# WKUP_CTRL_MMR0_CFG0 register map
Vendor: Texas Instruments
Registers are 32-bit, read-write, reset 0x0 unless marked. A register's access mark holds for its fields unless they carry their own. Offsets are as the file gives them; [hi:lo] are bit positions.

## WKUP_CTRL_MMR0_CFG0 (part 6 of 11)
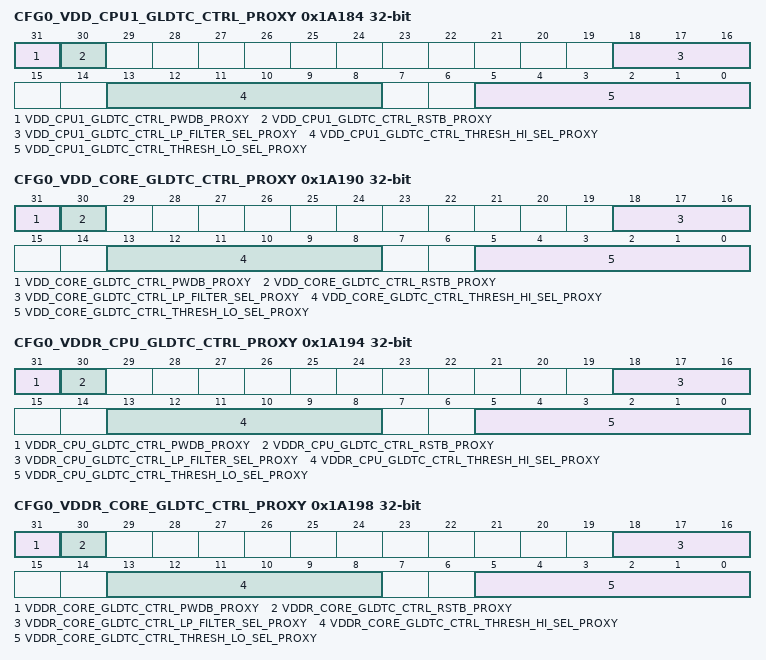
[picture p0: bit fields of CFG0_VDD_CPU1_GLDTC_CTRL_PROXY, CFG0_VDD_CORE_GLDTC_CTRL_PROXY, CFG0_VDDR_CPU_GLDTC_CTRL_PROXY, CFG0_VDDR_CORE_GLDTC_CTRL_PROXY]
0x1A184 CFG0_VDD_CPU1_GLDTC_CTRL_PROXY
  [31] VDD_CPU1_GLDTC_CTRL_PWDB_PROXY — Power down - active low. 0 - Disable all functions 1 - Enable glitch detectors
  [30] VDD_CPU1_GLDTC_CTRL_RSTB_PROXY — Reset - active low. To ensure proper operation, rstb must be not be de-asserted for at least 100 ns after power-up (pwdb de-asserted). Additionally, rstb must be toggled low at least 200 ns after any change in threshold or low-pass filter settings to prevent abnormal trigger events. 0 - Reset glitch detector flags 1 - Glitch detection flags are enabled
  [18:16] VDD_CPU1_GLDTC_CTRL_LP_FILTER_SEL_PROXY — Selects the glitch detect low-pass filter bandwidth Field values (Others are reserved): 3'b000 - 150 kHz 3'b001 - 125 kHz 3'b010 - 100 kHz 3'b011 - 80 kHz 3'b100 - 60 kHz 3'b101 - 45 kHz 3'b110 - 30 kHz 3'b111 - 15 kHz
  [13:8] VDD_CPU1_GLDTC_CTRL_THRESH_HI_SEL_PROXY — Selects the high voltage glitch threshold as a percentage of the monitored voltage Field values (Others are reserved): 6'b000000 - 93.5% of VDD 6'b000001 - 94.0% of VDD 6'b000010 - 94.5% of VDD 6'b000011 - 95.0% of VDD 6'b000100 - 95.5% of VDD 6'b000101 - 96.0% of VDD 6'b000110 - 96.5% of VDD 6'b000111 - 97.0% of VDD 6'b001000 - 97.5% of VDD 6'b001001 - 98.0% of VDD 6'b001010 - 98.5% of VDD 6'b001011 - 99.0% of VDD 6'b001100 - 99.5% of VDD 6'b001101 - 100.0% of VDD 6'b001110 - 100.5% of VDD 6'b001111 - 101.0% of VDD 6'b010000 - 101.5% of VDD 6'b010001 - 102.0% of VDD 6'b010010 - 102.5% of VDD 6'b010011 - 103.0% of VDD 6'b010100 - 103.5% of VDD 6'b010101 - 104.0% of VDD 6'b010110 - 104.5% of VDD 6'b010111 - 105.0% of VDD 6'b011000 - 105.5% of VDD 6'b011001 - 106.0% of VDD 6'b011010 - 106.5% of VDD 6'b011011 - 107.0% of VDD 6'b011100 - 107.5% of VDD 6'b011101 - 108.0% of VDD 6'b011110 - 108.5% of VDD 6'b011111 - 109.0% of VDD 6'b100000 - 109.5% of VDD 6'b100001 - 110.0% of VDD 6'b100010 - 111.0% of VDD 6'b100011 - 112.0% of VDD 6'b100100 - 113.0% of VDD 6'b100101 - 114.0% of VDD 6'b100110 - 115.0% of VDD 6'b100111 - 116.0% of VDD 6'b101000 - 117.0% of VDD 6'b101001 - 118.0% of VDD 6'b101010 - 119.0% of VDD 6'b101011 - 120.0% of VDD 6'b101100 - 121.0% of VDD 6'b101101 - 122.0% of VDD 6'b101110 - 123.0% of VDD 6'b101111 - 124.0% of VDD 6'b110000 - 125.0% of VDD 6'b110001 - 126.0% of VDD 6'b110010 - 127.0% of VDD 6'b110011 - 128.0% of VDD 6'b110100 - 129.0% of VDD 6'b110101 - 130.0% of VDD 6'b110110 - 131.0% of VDD 6'b110111 - 132.0% of VDD 6'b111000 - 133.0% of VDD 6'b111001 - 134.0% of VDD 6'b111010 - 135.0% of VDD 6'b111011 - 136.0% of VDD 6'b111100 - 137.0% of VDD 6'b111101 - 138.0% of VDD 6'b111110 - 139.0% of VDD 6'b111111 - 140.0% of VDD
  [5:0] VDD_CPU1_GLDTC_CTRL_THRESH_LO_SEL_PROXY — Selects the low voltage glitch threshold as a percentage of the monitored voltage Field values (Others are reserved): 6'b000000 - 106.5% of VDD 6'b000001 - 106.0% of VDD 6'b000010 - 105.5% of VDD 6'b000011 - 105.0% of VDD 6'b000100 - 104.5% of VDD 6'b000101 - 104.0% of VDD 6'b000110 - 103.5% of VDD 6'b000111 - 103.0% of VDD 6'b001000 - 102.5% of VDD 6'b001001 - 102.0% of VDD 6'b001010 - 101.5% of VDD 6'b001011 - 101.0% of VDD 6'b001100 - 100.5% of VDD 6'b001101 - 100.0% of VDD 6'b001110 - 99.5% of VDD 6'b001111 - 99.0% of VDD 6'b010000 - 98.5% of VDD 6'b010001 - 98.0% of VDD 6'b010010 - 97.5% of VDD 6'b010011 - 97.0% of VDD 6'b010100 - 96.5% of VDD 6'b010101 - 96.0% of VDD 6'b010110 - 95.5% of VDD 6'b010111 - 95.0% of VDD 6'b011000 - 94.5% of VDD 6'b011001 - 94.0% of VDD 6'b011010 - 93.5% of VDD 6'b011011 - 93.0% of VDD 6'b011100 - 92.5% of VDD 6'b011101 - 92.0% of VDD 6'b011110 - 91.5% of VDD 6'b011111 - 91.0% of VDD 6'b100000 - 90.5% of VDD 6'b100001 - 90.0% of VDD 6'b100010 - 89.0% of VDD 6'b100011 - 88.0% of VDD 6'b100100 - 87.0% of VDD 6'b100101 - 86.0% of VDD 6'b100110 - 85.0% of VDD 6'b100111 - 84.0% of VDD 6'b101000 - 83.0% of VDD 6'b101001 - 82.0% of VDD 6'b101010 - 81.0% of VDD 6'b101011 - 80.0% of VDD 6'b101100 - 79.0% of VDD 6'b101101 - 78.0% of VDD 6'b101110 - 77.0% of VDD 6'b101111 - 76.0% of VDD 6'b110000 - 75.0% of VDD 6'b110001 - 74.0% of VDD 6'b110010 - 73.0% of VDD 6'b110011 - 72.0% of VDD 6'b110100 - 71.0% of VDD 6'b110101 - 70.0% of VDD 6'b110110 - 69.0% of VDD 6'b110111 - 68.0% of VDD 6'b111000 - 67.0% of VDD 6'b111001 - 66.0% of VDD 6'b111010 - 65.0% of VDD 6'b111011 - 64.0% of VDD 6'b111100 - 63.0% of VDD 6'b111101 - 62.0% of VDD 6'b111110 - 61.0% of VDD 6'b111111 - 60.0% of VDD
0x1A190 CFG0_VDD_CORE_GLDTC_CTRL_PROXY — Controls the voltage glitch detector circuit monitoring the VDD_CORE voltage domain
  [31] VDD_CORE_GLDTC_CTRL_PWDB_PROXY — Power down - active low. 0 - Disable all functions 1 - Enable glitch detectors
  [30] VDD_CORE_GLDTC_CTRL_RSTB_PROXY — Reset - active low. To ensure proper operation, rstb must be not be de-asserted for at least 100 ns after power-up (pwdb de-asserted). Additionally, rstb must be toggled low at least 200 ns after any change in threshold or low-pass filter settings to prevent abnormal trigger events. 0 - Reset glitch detector flags 1 - Glitch detection flags are enabled
  [18:16] VDD_CORE_GLDTC_CTRL_LP_FILTER_SEL_PROXY — Selects the glitch detect low-pass filter bandwidth Field values (Others are reserved): 3'b000 - 150 kHz 3'b001 - 125 kHz 3'b010 - 100 kHz 3'b011 - 80 kHz 3'b100 - 60 kHz 3'b101 - 45 kHz 3'b110 - 30 kHz 3'b111 - 15 kHz
  [13:8] VDD_CORE_GLDTC_CTRL_THRESH_HI_SEL_PROXY — Selects the high voltage glitch threshold as a percentage of the monitored voltage Field values (Others are reserved): 6'b000000 - 93.5% of VDD 6'b000001 - 94.0% of VDD 6'b000010 - 94.5% of VDD 6'b000011 - 95.0% of VDD 6'b000100 - 95.5% of VDD 6'b000101 - 96.0% of VDD 6'b000110 - 96.5% of VDD 6'b000111 - 97.0% of VDD 6'b001000 - 97.5% of VDD 6'b001001 - 98.0% of VDD 6'b001010 - 98.5% of VDD 6'b001011 - 99.0% of VDD 6'b001100 - 99.5% of VDD 6'b001101 - 100.0% of VDD 6'b001110 - 100.5% of VDD 6'b001111 - 101.0% of VDD 6'b010000 - 101.5% of VDD 6'b010001 - 102.0% of VDD 6'b010010 - 102.5% of VDD 6'b010011 - 103.0% of VDD 6'b010100 - 103.5% of VDD 6'b010101 - 104.0% of VDD 6'b010110 - 104.5% of VDD 6'b010111 - 105.0% of VDD 6'b011000 - 105.5% of VDD 6'b011001 - 106.0% of VDD 6'b011010 - 106.5% of VDD 6'b011011 - 107.0% of VDD 6'b011100 - 107.5% of VDD 6'b011101 - 108.0% of VDD 6'b011110 - 108.5% of VDD 6'b011111 - 109.0% of VDD 6'b100000 - 109.5% of VDD 6'b100001 - 110.0% of VDD 6'b100010 - 111.0% of VDD 6'b100011 - 112.0% of VDD 6'b100100 - 113.0% of VDD 6'b100101 - 114.0% of VDD 6'b100110 - 115.0% of VDD 6'b100111 - 116.0% of VDD 6'b101000 - 117.0% of VDD 6'b101001 - 118.0% of VDD 6'b101010 - 119.0% of VDD 6'b101011 - 120.0% of VDD 6'b101100 - 121.0% of VDD 6'b101101 - 122.0% of VDD 6'b101110 - 123.0% of VDD 6'b101111 - 124.0% of VDD 6'b110000 - 125.0% of VDD 6'b110001 - 126.0% of VDD 6'b110010 - 127.0% of VDD 6'b110011 - 128.0% of VDD 6'b110100 - 129.0% of VDD 6'b110101 - 130.0% of VDD 6'b110110 - 131.0% of VDD 6'b110111 - 132.0% of VDD 6'b111000 - 133.0% of VDD 6'b111001 - 134.0% of VDD 6'b111010 - 135.0% of VDD 6'b111011 - 136.0% of VDD 6'b111100 - 137.0% of VDD 6'b111101 - 138.0% of VDD 6'b111110 - 139.0% of VDD 6'b111111 - 140.0% of VDD
  [5:0] VDD_CORE_GLDTC_CTRL_THRESH_LO_SEL_PROXY — Selects the low voltage glitch threshold as a percentage of the monitored voltage Field values (Others are reserved): 6'b000000 - 106.5% of VDD 6'b000001 - 106.0% of VDD 6'b000010 - 105.5% of VDD 6'b000011 - 105.0% of VDD 6'b000100 - 104.5% of VDD 6'b000101 - 104.0% of VDD 6'b000110 - 103.5% of VDD 6'b000111 - 103.0% of VDD 6'b001000 - 102.5% of VDD 6'b001001 - 102.0% of VDD 6'b001010 - 101.5% of VDD 6'b001011 - 101.0% of VDD 6'b001100 - 100.5% of VDD 6'b001101 - 100.0% of VDD 6'b001110 - 99.5% of VDD 6'b001111 - 99.0% of VDD 6'b010000 - 98.5% of VDD 6'b010001 - 98.0% of VDD 6'b010010 - 97.5% of VDD 6'b010011 - 97.0% of VDD 6'b010100 - 96.5% of VDD 6'b010101 - 96.0% of VDD 6'b010110 - 95.5% of VDD 6'b010111 - 95.0% of VDD 6'b011000 - 94.5% of VDD 6'b011001 - 94.0% of VDD 6'b011010 - 93.5% of VDD 6'b011011 - 93.0% of VDD 6'b011100 - 92.5% of VDD 6'b011101 - 92.0% of VDD 6'b011110 - 91.5% of VDD 6'b011111 - 91.0% of VDD 6'b100000 - 90.5% of VDD 6'b100001 - 90.0% of VDD 6'b100010 - 89.0% of VDD 6'b100011 - 88.0% of VDD 6'b100100 - 87.0% of VDD 6'b100101 - 86.0% of VDD 6'b100110 - 85.0% of VDD 6'b100111 - 84.0% of VDD 6'b101000 - 83.0% of VDD 6'b101001 - 82.0% of VDD 6'b101010 - 81.0% of VDD 6'b101011 - 80.0% of VDD 6'b101100 - 79.0% of VDD 6'b101101 - 78.0% of VDD 6'b101110 - 77.0% of VDD 6'b101111 - 76.0% of VDD 6'b110000 - 75.0% of VDD 6'b110001 - 74.0% of VDD 6'b110010 - 73.0% of VDD 6'b110011 - 72.0% of VDD 6'b110100 - 71.0% of VDD 6'b110101 - 70.0% of VDD 6'b110110 - 69.0% of VDD 6'b110111 - 68.0% of VDD 6'b111000 - 67.0% of VDD 6'b111001 - 66.0% of VDD 6'b111010 - 65.0% of VDD 6'b111011 - 64.0% of VDD 6'b111100 - 63.0% of VDD 6'b111101 - 62.0% of VDD 6'b111110 - 61.0% of VDD 6'b111111 - 60.0% of VDD
0x1A194 CFG0_VDDR_CPU_GLDTC_CTRL_PROXY — Controls the voltage glitch detector circuit monitoring the VDDR_CPU 0 voltage domain
  [31] VDDR_CPU_GLDTC_CTRL_PWDB_PROXY — Power down - active low. 0 - Disable all functions 1 - Enable glitch detectors
  [30] VDDR_CPU_GLDTC_CTRL_RSTB_PROXY — Reset - active low. To ensure proper operation, rstb must be not be de-asserted for at least 100 ns after power-up (pwdb de-asserted). Additionally, rstb must be toggled low at least 200 ns after any change in threshold or low-pass filter settings to prevent abnormal trigger events. 0 - Reset glitch detector flags 1 - Glitch detection flags are enabled
  [18:16] VDDR_CPU_GLDTC_CTRL_LP_FILTER_SEL_PROXY — Selects the glitch detect low-pass filter bandwidth Field values (Others are reserved): 3'b000 - 150 kHz 3'b001 - 125 kHz 3'b010 - 100 kHz 3'b011 - 80 kHz 3'b100 - 60 kHz 3'b101 - 45 kHz 3'b110 - 30 kHz 3'b111 - 15 kHz
  [13:8] VDDR_CPU_GLDTC_CTRL_THRESH_HI_SEL_PROXY — Selects the high voltage glitch threshold as a percentage of the monitored voltage Field values (Others are reserved): 6'b000000 - 93.5% of VDD 6'b000001 - 94.0% of VDD 6'b000010 - 94.5% of VDD 6'b000011 - 95.0% of VDD 6'b000100 - 95.5% of VDD 6'b000101 - 96.0% of VDD 6'b000110 - 96.5% of VDD 6'b000111 - 97.0% of VDD 6'b001000 - 97.5% of VDD 6'b001001 - 98.0% of VDD 6'b001010 - 98.5% of VDD 6'b001011 - 99.0% of VDD 6'b001100 - 99.5% of VDD 6'b001101 - 100.0% of VDD 6'b001110 - 100.5% of VDD 6'b001111 - 101.0% of VDD 6'b010000 - 101.5% of VDD 6'b010001 - 102.0% of VDD 6'b010010 - 102.5% of VDD 6'b010011 - 103.0% of VDD 6'b010100 - 103.5% of VDD 6'b010101 - 104.0% of VDD 6'b010110 - 104.5% of VDD 6'b010111 - 105.0% of VDD 6'b011000 - 105.5% of VDD 6'b011001 - 106.0% of VDD 6'b011010 - 106.5% of VDD 6'b011011 - 107.0% of VDD 6'b011100 - 107.5% of VDD 6'b011101 - 108.0% of VDD 6'b011110 - 108.5% of VDD 6'b011111 - 109.0% of VDD 6'b100000 - 109.5% of VDD 6'b100001 - 110.0% of VDD 6'b100010 - 111.0% of VDD 6'b100011 - 112.0% of VDD 6'b100100 - 113.0% of VDD 6'b100101 - 114.0% of VDD 6'b100110 - 115.0% of VDD 6'b100111 - 116.0% of VDD 6'b101000 - 117.0% of VDD 6'b101001 - 118.0% of VDD 6'b101010 - 119.0% of VDD 6'b101011 - 120.0% of VDD 6'b101100 - 121.0% of VDD 6'b101101 - 122.0% of VDD 6'b101110 - 123.0% of VDD 6'b101111 - 124.0% of VDD 6'b110000 - 125.0% of VDD 6'b110001 - 126.0% of VDD 6'b110010 - 127.0% of VDD 6'b110011 - 128.0% of VDD 6'b110100 - 129.0% of VDD 6'b110101 - 130.0% of VDD 6'b110110 - 131.0% of VDD 6'b110111 - 132.0% of VDD 6'b111000 - 133.0% of VDD 6'b111001 - 134.0% of VDD 6'b111010 - 135.0% of VDD 6'b111011 - 136.0% of VDD 6'b111100 - 137.0% of VDD 6'b111101 - 138.0% of VDD 6'b111110 - 139.0% of VDD 6'b111111 - 140.0% of VDD
  [5:0] VDDR_CPU_GLDTC_CTRL_THRESH_LO_SEL_PROXY — Selects the low voltage glitch threshold as a percentage of the monitored voltage Field values (Others are reserved): 6'b000000 - 106.5% of VDD 6'b000001 - 106.0% of VDD 6'b000010 - 105.5% of VDD 6'b000011 - 105.0% of VDD 6'b000100 - 104.5% of VDD 6'b000101 - 104.0% of VDD 6'b000110 - 103.5% of VDD 6'b000111 - 103.0% of VDD 6'b001000 - 102.5% of VDD 6'b001001 - 102.0% of VDD 6'b001010 - 101.5% of VDD 6'b001011 - 101.0% of VDD 6'b001100 - 100.5% of VDD 6'b001101 - 100.0% of VDD 6'b001110 - 99.5% of VDD 6'b001111 - 99.0% of VDD 6'b010000 - 98.5% of VDD 6'b010001 - 98.0% of VDD 6'b010010 - 97.5% of VDD 6'b010011 - 97.0% of VDD 6'b010100 - 96.5% of VDD 6'b010101 - 96.0% of VDD 6'b010110 - 95.5% of VDD 6'b010111 - 95.0% of VDD 6'b011000 - 94.5% of VDD 6'b011001 - 94.0% of VDD 6'b011010 - 93.5% of VDD 6'b011011 - 93.0% of VDD 6'b011100 - 92.5% of VDD 6'b011101 - 92.0% of VDD 6'b011110 - 91.5% of VDD 6'b011111 - 91.0% of VDD 6'b100000 - 90.5% of VDD 6'b100001 - 90.0% of VDD 6'b100010 - 89.0% of VDD 6'b100011 - 88.0% of VDD 6'b100100 - 87.0% of VDD 6'b100101 - 86.0% of VDD 6'b100110 - 85.0% of VDD 6'b100111 - 84.0% of VDD 6'b101000 - 83.0% of VDD 6'b101001 - 82.0% of VDD 6'b101010 - 81.0% of VDD 6'b101011 - 80.0% of VDD 6'b101100 - 79.0% of VDD 6'b101101 - 78.0% of VDD 6'b101110 - 77.0% of VDD 6'b101111 - 76.0% of VDD 6'b110000 - 75.0% of VDD 6'b110001 - 74.0% of VDD 6'b110010 - 73.0% of VDD 6'b110011 - 72.0% of VDD 6'b110100 - 71.0% of VDD 6'b110101 - 70.0% of VDD 6'b110110 - 69.0% of VDD 6'b110111 - 68.0% of VDD 6'b111000 - 67.0% of VDD 6'b111001 - 66.0% of VDD 6'b111010 - 65.0% of VDD 6'b111011 - 64.0% of VDD 6'b111100 - 63.0% of VDD 6'b111101 - 62.0% of VDD 6'b111110 - 61.0% of VDD 6'b111111 - 60.0% of VDD
0x1A198 CFG0_VDDR_CORE_GLDTC_CTRL_PROXY — Controls the voltage glitch detector circuit monitoring the VDDR_CORE voltage domain
  [31] VDDR_CORE_GLDTC_CTRL_PWDB_PROXY — Power down - active low. 0 - Disable all functions 1 - Enable glitch detectors
  [30] VDDR_CORE_GLDTC_CTRL_RSTB_PROXY — Reset - active low. To ensure proper operation, rstb must be not be de-asserted for at least 100 ns after power-up (pwdb de-asserted). Additionally, rstb must be toggled low at least 200 ns after any change in threshold or low-pass filter settings to prevent abnormal trigger events. 0 - Reset glitch detector flags 1 - Glitch detection flags are enabled
  [18:16] VDDR_CORE_GLDTC_CTRL_LP_FILTER_SEL_PROXY — Selects the glitch detect low-pass filter bandwidth Field values (Others are reserved): 3'b000 - 150 kHz 3'b001 - 125 kHz 3'b010 - 100 kHz 3'b011 - 80 kHz 3'b100 - 60 kHz 3'b101 - 45 kHz 3'b110 - 30 kHz 3'b111 - 15 kHz
  [13:8] VDDR_CORE_GLDTC_CTRL_THRESH_HI_SEL_PROXY — Selects the high voltage glitch threshold as a percentage of the monitored voltage Field values (Others are reserved): 6'b000000 - 93.5% of VDD 6'b000001 - 94.0% of VDD 6'b000010 - 94.5% of VDD 6'b000011 - 95.0% of VDD 6'b000100 - 95.5% of VDD 6'b000101 - 96.0% of VDD 6'b000110 - 96.5% of VDD 6'b000111 - 97.0% of VDD 6'b001000 - 97.5% of VDD 6'b001001 - 98.0% of VDD 6'b001010 - 98.5% of VDD 6'b001011 - 99.0% of VDD 6'b001100 - 99.5% of VDD 6'b001101 - 100.0% of VDD 6'b001110 - 100.5% of VDD 6'b001111 - 101.0% of VDD 6'b010000 - 101.5% of VDD 6'b010001 - 102.0% of VDD 6'b010010 - 102.5% of VDD 6'b010011 - 103.0% of VDD 6'b010100 - 103.5% of VDD 6'b010101 - 104.0% of VDD 6'b010110 - 104.5% of VDD 6'b010111 - 105.0% of VDD 6'b011000 - 105.5% of VDD 6'b011001 - 106.0% of VDD 6'b011010 - 106.5% of VDD 6'b011011 - 107.0% of VDD 6'b011100 - 107.5% of VDD 6'b011101 - 108.0% of VDD 6'b011110 - 108.5% of VDD 6'b011111 - 109.0% of VDD 6'b100000 - 109.5% of VDD 6'b100001 - 110.0% of VDD 6'b100010 - 111.0% of VDD 6'b100011 - 112.0% of VDD 6'b100100 - 113.0% of VDD 6'b100101 - 114.0% of VDD 6'b100110 - 115.0% of VDD 6'b100111 - 116.0% of VDD 6'b101000 - 117.0% of VDD 6'b101001 - 118.0% of VDD 6'b101010 - 119.0% of VDD 6'b101011 - 120.0% of VDD 6'b101100 - 121.0% of VDD 6'b101101 - 122.0% of VDD 6'b101110 - 123.0% of VDD 6'b101111 - 124.0% of VDD 6'b110000 - 125.0% of VDD 6'b110001 - 126.0% of VDD 6'b110010 - 127.0% of VDD 6'b110011 - 128.0% of VDD 6'b110100 - 129.0% of VDD 6'b110101 - 130.0% of VDD 6'b110110 - 131.0% of VDD 6'b110111 - 132.0% of VDD 6'b111000 - 133.0% of VDD 6'b111001 - 134.0% of VDD 6'b111010 - 135.0% of VDD 6'b111011 - 136.0% of VDD 6'b111100 - 137.0% of VDD 6'b111101 - 138.0% of VDD 6'b111110 - 139.0% of VDD 6'b111111 - 140.0% of VDD
  [5:0] VDDR_CORE_GLDTC_CTRL_THRESH_LO_SEL_PROXY — Selects the low voltage glitch threshold as a percentage of the monitored voltage Field values (Others are reserved): 6'b000000 - 106.5% of VDD 6'b000001 - 106.0% of VDD 6'b000010 - 105.5% of VDD 6'b000011 - 105.0% of VDD 6'b000100 - 104.5% of VDD 6'b000101 - 104.0% of VDD 6'b000110 - 103.5% of VDD 6'b000111 - 103.0% of VDD 6'b001000 - 102.5% of VDD 6'b001001 - 102.0% of VDD 6'b001010 - 101.5% of VDD 6'b001011 - 101.0% of VDD 6'b001100 - 100.5% of VDD 6'b001101 - 100.0% of VDD 6'b001110 - 99.5% of VDD 6'b001111 - 99.0% of VDD 6'b010000 - 98.5% of VDD 6'b010001 - 98.0% of VDD 6'b010010 - 97.5% of VDD 6'b010011 - 97.0% of VDD 6'b010100 - 96.5% of VDD 6'b010101 - 96.0% of VDD 6'b010110 - 95.5% of VDD 6'b010111 - 95.0% of VDD 6'b011000 - 94.5% of VDD 6'b011001 - 94.0% of VDD 6'b011010 - 93.5% of VDD 6'b011011 - 93.0% of VDD 6'b011100 - 92.5% of VDD 6'b011101 - 92.0% of VDD 6'b011110 - 91.5% of VDD 6'b011111 - 91.0% of VDD 6'b100000 - 90.5% of VDD 6'b100001 - 90.0% of VDD 6'b100010 - 89.0% of VDD 6'b100011 - 88.0% of VDD 6'b100100 - 87.0% of VDD 6'b100101 - 86.0% of VDD 6'b100110 - 85.0% of VDD 6'b100111 - 84.0% of VDD 6'b101000 - 83.0% of VDD 6'b101001 - 82.0% of VDD 6'b101010 - 81.0% of VDD 6'b101011 - 80.0% of VDD 6'b101100 - 79.0% of VDD 6'b101101 - 78.0% of VDD 6'b101110 - 77.0% of VDD 6'b101111 - 76.0% of VDD 6'b110000 - 75.0% of VDD 6'b110001 - 74.0% of VDD 6'b110010 - 73.0% of VDD 6'b110011 - 72.0% of VDD 6'b110100 - 71.0% of VDD 6'b110101 - 70.0% of VDD 6'b110110 - 69.0% of VDD 6'b110111 - 68.0% of VDD 6'b111000 - 67.0% of VDD 6'b111001 - 66.0% of VDD 6'b111010 - 65.0% of VDD 6'b111011 - 64.0% of VDD 6'b111100 - 63.0% of VDD 6'b111101 - 62.0% of VDD 6'b111110 - 61.0% of VDD 6'b111111 - 60.0% of VDD
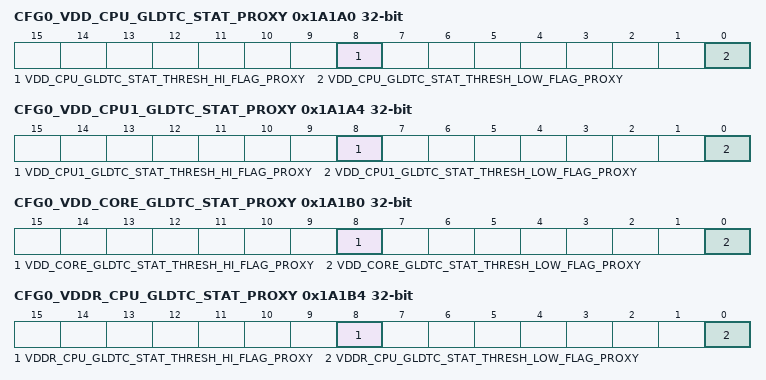
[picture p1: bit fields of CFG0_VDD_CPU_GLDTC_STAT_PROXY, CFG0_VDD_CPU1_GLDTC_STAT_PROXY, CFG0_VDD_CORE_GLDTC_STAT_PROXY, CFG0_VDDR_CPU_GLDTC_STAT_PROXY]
0x1A1A0 CFG0_VDD_CPU_GLDTC_STAT_PROXY ro — Shows the status of the voltage glitch detector circuit monitoring the VDD_CPU voltage domain
  [8] VDD_CPU_GLDTC_STAT_THRESH_HI_FLAG_PROXY — High voltage flag. This flag is cleared by clearing the VDD_CPU_GLDTC_CTRL_rstb bit. 0 - No high voltage detected 1 - Voltage above the high voltage threshold was detected.
  [0] VDD_CPU_GLDTC_STAT_THRESH_LOW_FLAG_PROXY — Low voltage flag. This flag is cleared by clearing the VDD_CPU_GLDTC_CTRL_rstb bit. 0 - No low voltage detected 1 - Voltage below the low voltage threshold was detected.
0x1A1A4 CFG0_VDD_CPU1_GLDTC_STAT_PROXY ro — Shows the status of the voltage glitch detector circuit monitoring the VDD_CPU1 voltage domain (Used for VDD_DDR0)
  [8] VDD_CPU1_GLDTC_STAT_THRESH_HI_FLAG_PROXY — High voltage flag. This flag is cleared by clearing the VDD_CPU1_GLDTC_CTRL_rstb bit. 0 - No high voltage detected 1 - Voltage above the high voltage threshold was detected.
  [0] VDD_CPU1_GLDTC_STAT_THRESH_LOW_FLAG_PROXY — Low voltage flag. This flag is cleared by clearing the VDD_CPU1_GLDTC_CTRL_rstb bit. 0 - No low voltage detected 1 - Voltage below the low voltage threshold was detected.
0x1A1B0 CFG0_VDD_CORE_GLDTC_STAT_PROXY ro — Shows the status of the voltage glitch detector circuit monitoring the VDD_CORE voltage domain
  [8] VDD_CORE_GLDTC_STAT_THRESH_HI_FLAG_PROXY — High voltage flag. This flag is cleared by clearing the VDD_CORE_GLDTC_CTRL_rstb bit. 0 - No high voltage detected 1 - Voltage above the high voltage threshold was detected.
  [0] VDD_CORE_GLDTC_STAT_THRESH_LOW_FLAG_PROXY — Low voltage flag. This flag is cleared by clearing the VDD_CORE_GLDTC_CTRL_rstb bit. 0 - No low voltage detected 1 - Voltage below the low voltage threshold was detected.
0x1A1B4 CFG0_VDDR_CPU_GLDTC_STAT_PROXY ro — Shows the status of the voltage glitch detector circuit monitoring the VDDR_CPU voltage domain
  [8] VDDR_CPU_GLDTC_STAT_THRESH_HI_FLAG_PROXY — High voltage flag. This flag is cleared by clearing the VDDR_CPU_GLDTC_CTRL_rstb bit. 0 - No high voltage detected 1 - Voltage above the high voltage threshold was detected.
  [0] VDDR_CPU_GLDTC_STAT_THRESH_LOW_FLAG_PROXY — Low voltage flag. This flag is cleared by clearing the VDDR_CPU_GLDTC_CTRL_rstb bit. 0 - No low voltage detected 1 - Voltage below the low voltage threshold was detected.
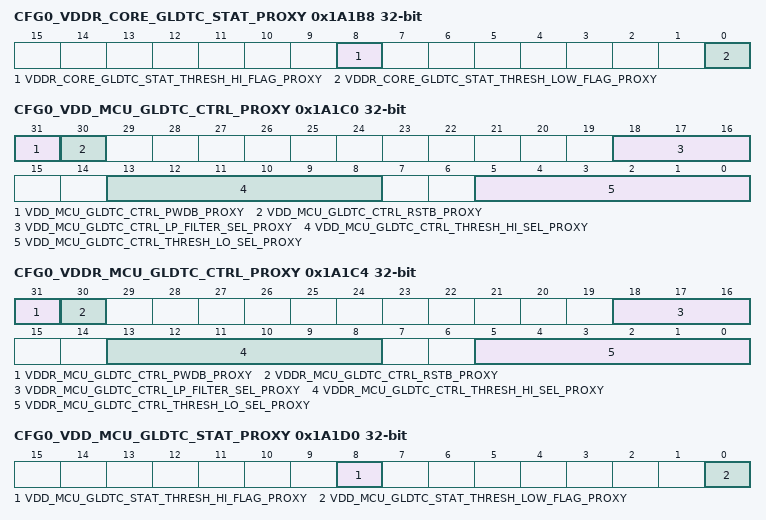
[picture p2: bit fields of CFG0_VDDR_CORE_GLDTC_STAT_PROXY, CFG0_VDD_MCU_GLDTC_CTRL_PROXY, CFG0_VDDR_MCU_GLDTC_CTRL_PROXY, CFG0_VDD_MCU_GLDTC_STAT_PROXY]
0x1A1B8 CFG0_VDDR_CORE_GLDTC_STAT_PROXY ro — Shows the status of the voltage glitch detector circuit monitoring the VDDR_CORE voltage domain
  [8] VDDR_CORE_GLDTC_STAT_THRESH_HI_FLAG_PROXY — High voltage flag. This flag is cleared by clearing the VDDR_CORE_GLDTC_CTRL_rstb bit. 0 - No high voltage detected 1 - Voltage above the high voltage threshold was detected.
  [0] VDDR_CORE_GLDTC_STAT_THRESH_LOW_FLAG_PROXY — Low voltage flag. This flag is cleared by clearing the VDDR_CORE_GLDTC_CTRL_rstb bit. 0 - No low voltage detected 1 - Voltage below the low voltage threshold was detected.
0x1A1C0 CFG0_VDD_MCU_GLDTC_CTRL_PROXY — Controls the voltage glitch detector circuit monitoring the VDD_MCU voltage domain
  [31] VDD_MCU_GLDTC_CTRL_PWDB_PROXY — Power down - active low. 0 - Disable all functions 1 - Enable glitch detectors
  [30] VDD_MCU_GLDTC_CTRL_RSTB_PROXY — Reset - active low. To ensure proper operation, rstb must be not be de-asserted for at least 100 ns after power-up (pwdb de-asserted). Additionally, rstb must be toggled low at least 200 ns after any change in threshold or low-pass filter settings to prevent abnormal trigger events. 0 - Reset glitch detector flags 1 - Glitch detection flags are enabled
  [18:16] VDD_MCU_GLDTC_CTRL_LP_FILTER_SEL_PROXY — Selects the glitch detect low-pass filter bandwidth Field values (Others are reserved): 3'b000 - 150 kHz 3'b001 - 125 kHz 3'b010 - 100 kHz 3'b011 - 80 kHz 3'b100 - 60 kHz 3'b101 - 45 kHz 3'b110 - 30 kHz 3'b111 - 15 kHz
  [13:8] VDD_MCU_GLDTC_CTRL_THRESH_HI_SEL_PROXY — Selects the high voltage glitch threshold as a percentage of the monitored voltage Field values (Others are reserved): 6'b000000 - 93.5% of VDD 6'b000001 - 94.0% of VDD 6'b000010 - 94.5% of VDD 6'b000011 - 95.0% of VDD 6'b000100 - 95.5% of VDD 6'b000101 - 96.0% of VDD 6'b000110 - 96.5% of VDD 6'b000111 - 97.0% of VDD 6'b001000 - 97.5% of VDD 6'b001001 - 98.0% of VDD 6'b001010 - 98.5% of VDD 6'b001011 - 99.0% of VDD 6'b001100 - 99.5% of VDD 6'b001101 - 100.0% of VDD 6'b001110 - 100.5% of VDD 6'b001111 - 101.0% of VDD 6'b010000 - 101.5% of VDD 6'b010001 - 102.0% of VDD 6'b010010 - 102.5% of VDD 6'b010011 - 103.0% of VDD 6'b010100 - 103.5% of VDD 6'b010101 - 104.0% of VDD 6'b010110 - 104.5% of VDD 6'b010111 - 105.0% of VDD 6'b011000 - 105.5% of VDD 6'b011001 - 106.0% of VDD 6'b011010 - 106.5% of VDD 6'b011011 - 107.0% of VDD 6'b011100 - 107.5% of VDD 6'b011101 - 108.0% of VDD 6'b011110 - 108.5% of VDD 6'b011111 - 109.0% of VDD 6'b100000 - 109.5% of VDD 6'b100001 - 110.0% of VDD 6'b100010 - 111.0% of VDD 6'b100011 - 112.0% of VDD 6'b100100 - 113.0% of VDD 6'b100101 - 114.0% of VDD 6'b100110 - 115.0% of VDD 6'b100111 - 116.0% of VDD 6'b101000 - 117.0% of VDD 6'b101001 - 118.0% of VDD 6'b101010 - 119.0% of VDD 6'b101011 - 120.0% of VDD 6'b101100 - 121.0% of VDD 6'b101101 - 122.0% of VDD 6'b101110 - 123.0% of VDD 6'b101111 - 124.0% of VDD 6'b110000 - 125.0% of VDD 6'b110001 - 126.0% of VDD 6'b110010 - 127.0% of VDD 6'b110011 - 128.0% of VDD 6'b110100 - 129.0% of VDD 6'b110101 - 130.0% of VDD 6'b110110 - 131.0% of VDD 6'b110111 - 132.0% of VDD 6'b111000 - 133.0% of VDD 6'b111001 - 134.0% of VDD 6'b111010 - 135.0% of VDD 6'b111011 - 136.0% of VDD 6'b111100 - 137.0% of VDD 6'b111101 - 138.0% of VDD 6'b111110 - 139.0% of VDD 6'b111111 - 140.0% of VDD
  [5:0] VDD_MCU_GLDTC_CTRL_THRESH_LO_SEL_PROXY — Selects the low voltage glitch threshold as a percentage of the monitored voltage Field values (Others are reserved): 6'b000000 - 106.5% of VDD 6'b000001 - 106.0% of VDD 6'b000010 - 105.5% of VDD 6'b000011 - 105.0% of VDD 6'b000100 - 104.5% of VDD 6'b000101 - 104.0% of VDD 6'b000110 - 103.5% of VDD 6'b000111 - 103.0% of VDD 6'b001000 - 102.5% of VDD 6'b001001 - 102.0% of VDD 6'b001010 - 101.5% of VDD 6'b001011 - 101.0% of VDD 6'b001100 - 100.5% of VDD 6'b001101 - 100.0% of VDD 6'b001110 - 99.5% of VDD 6'b001111 - 99.0% of VDD 6'b010000 - 98.5% of VDD 6'b010001 - 98.0% of VDD 6'b010010 - 97.5% of VDD 6'b010011 - 97.0% of VDD 6'b010100 - 96.5% of VDD 6'b010101 - 96.0% of VDD 6'b010110 - 95.5% of VDD 6'b010111 - 95.0% of VDD 6'b011000 - 94.5% of VDD 6'b011001 - 94.0% of VDD 6'b011010 - 93.5% of VDD 6'b011011 - 93.0% of VDD 6'b011100 - 92.5% of VDD 6'b011101 - 92.0% of VDD 6'b011110 - 91.5% of VDD 6'b011111 - 91.0% of VDD 6'b100000 - 90.5% of VDD 6'b100001 - 90.0% of VDD 6'b100010 - 89.0% of VDD 6'b100011 - 88.0% of VDD 6'b100100 - 87.0% of VDD 6'b100101 - 86.0% of VDD 6'b100110 - 85.0% of VDD 6'b100111 - 84.0% of VDD 6'b101000 - 83.0% of VDD 6'b101001 - 82.0% of VDD 6'b101010 - 81.0% of VDD 6'b101011 - 80.0% of VDD 6'b101100 - 79.0% of VDD 6'b101101 - 78.0% of VDD 6'b101110 - 77.0% of VDD 6'b101111 - 76.0% of VDD 6'b110000 - 75.0% of VDD 6'b110001 - 74.0% of VDD 6'b110010 - 73.0% of VDD 6'b110011 - 72.0% of VDD 6'b110100 - 71.0% of VDD 6'b110101 - 70.0% of VDD 6'b110110 - 69.0% of VDD 6'b110111 - 68.0% of VDD 6'b111000 - 67.0% of VDD 6'b111001 - 66.0% of VDD 6'b111010 - 65.0% of VDD 6'b111011 - 64.0% of VDD 6'b111100 - 63.0% of VDD 6'b111101 - 62.0% of VDD 6'b111110 - 61.0% of VDD 6'b111111 - 60.0% of VDD
0x1A1C4 CFG0_VDDR_MCU_GLDTC_CTRL_PROXY — Controls the voltage glitch detector circuit monitoring the VDDR_MCU voltage domain
  [31] VDDR_MCU_GLDTC_CTRL_PWDB_PROXY — Power down - active low. 0 - Disable all functions 1 - Enable glitch detectors
  [30] VDDR_MCU_GLDTC_CTRL_RSTB_PROXY — Reset - active low. To ensure proper operation, rstb must be not be de-asserted for at least 100 ns after power-up (pwdb de-asserted). Additionally, rstb must be toggled low at least 200 ns after any change in threshold or low-pass filter settings to prevent abnormal trigger events. 0 - Reset glitch detector flags 1 - Glitch detection flags are enabled
  [18:16] VDDR_MCU_GLDTC_CTRL_LP_FILTER_SEL_PROXY — Selects the glitch detect low-pass filter bandwidth Field values (Others are reserved): 3'b000 - 150 kHz 3'b001 - 125 kHz 3'b010 - 100 kHz 3'b011 - 80 kHz 3'b100 - 60 kHz 3'b101 - 45 kHz 3'b110 - 30 kHz 3'b111 - 15 kHz
  [13:8] VDDR_MCU_GLDTC_CTRL_THRESH_HI_SEL_PROXY — Selects the high voltage glitch threshold as a percentage of the monitored voltage Field values (Others are reserved): 6'b000000 - 93.5% of VDD 6'b000001 - 94.0% of VDD 6'b000010 - 94.5% of VDD 6'b000011 - 95.0% of VDD 6'b000100 - 95.5% of VDD 6'b000101 - 96.0% of VDD 6'b000110 - 96.5% of VDD 6'b000111 - 97.0% of VDD 6'b001000 - 97.5% of VDD 6'b001001 - 98.0% of VDD 6'b001010 - 98.5% of VDD 6'b001011 - 99.0% of VDD 6'b001100 - 99.5% of VDD 6'b001101 - 100.0% of VDD 6'b001110 - 100.5% of VDD 6'b001111 - 101.0% of VDD 6'b010000 - 101.5% of VDD 6'b010001 - 102.0% of VDD 6'b010010 - 102.5% of VDD 6'b010011 - 103.0% of VDD 6'b010100 - 103.5% of VDD 6'b010101 - 104.0% of VDD 6'b010110 - 104.5% of VDD 6'b010111 - 105.0% of VDD 6'b011000 - 105.5% of VDD 6'b011001 - 106.0% of VDD 6'b011010 - 106.5% of VDD 6'b011011 - 107.0% of VDD 6'b011100 - 107.5% of VDD 6'b011101 - 108.0% of VDD 6'b011110 - 108.5% of VDD 6'b011111 - 109.0% of VDD 6'b100000 - 109.5% of VDD 6'b100001 - 110.0% of VDD 6'b100010 - 111.0% of VDD 6'b100011 - 112.0% of VDD 6'b100100 - 113.0% of VDD 6'b100101 - 114.0% of VDD 6'b100110 - 115.0% of VDD 6'b100111 - 116.0% of VDD 6'b101000 - 117.0% of VDD 6'b101001 - 118.0% of VDD 6'b101010 - 119.0% of VDD 6'b101011 - 120.0% of VDD 6'b101100 - 121.0% of VDD 6'b101101 - 122.0% of VDD 6'b101110 - 123.0% of VDD 6'b101111 - 124.0% of VDD 6'b110000 - 125.0% of VDD 6'b110001 - 126.0% of VDD 6'b110010 - 127.0% of VDD 6'b110011 - 128.0% of VDD 6'b110100 - 129.0% of VDD 6'b110101 - 130.0% of VDD 6'b110110 - 131.0% of VDD 6'b110111 - 132.0% of VDD 6'b111000 - 133.0% of VDD 6'b111001 - 134.0% of VDD 6'b111010 - 135.0% of VDD 6'b111011 - 136.0% of VDD 6'b111100 - 137.0% of VDD 6'b111101 - 138.0% of VDD 6'b111110 - 139.0% of VDD 6'b111111 - 140.0% of VDD
  [5:0] VDDR_MCU_GLDTC_CTRL_THRESH_LO_SEL_PROXY — Selects the low voltage glitch threshold as a percentage of the monitored voltage Field values (Others are reserved): 6'b000000 - 106.5% of VDD 6'b000001 - 106.0% of VDD 6'b000010 - 105.5% of VDD 6'b000011 - 105.0% of VDD 6'b000100 - 104.5% of VDD 6'b000101 - 104.0% of VDD 6'b000110 - 103.5% of VDD 6'b000111 - 103.0% of VDD 6'b001000 - 102.5% of VDD 6'b001001 - 102.0% of VDD 6'b001010 - 101.5% of VDD 6'b001011 - 101.0% of VDD 6'b001100 - 100.5% of VDD 6'b001101 - 100.0% of VDD 6'b001110 - 99.5% of VDD 6'b001111 - 99.0% of VDD 6'b010000 - 98.5% of VDD 6'b010001 - 98.0% of VDD 6'b010010 - 97.5% of VDD 6'b010011 - 97.0% of VDD 6'b010100 - 96.5% of VDD 6'b010101 - 96.0% of VDD 6'b010110 - 95.5% of VDD 6'b010111 - 95.0% of VDD 6'b011000 - 94.5% of VDD 6'b011001 - 94.0% of VDD 6'b011010 - 93.5% of VDD 6'b011011 - 93.0% of VDD 6'b011100 - 92.5% of VDD 6'b011101 - 92.0% of VDD 6'b011110 - 91.5% of VDD 6'b011111 - 91.0% of VDD 6'b100000 - 90.5% of VDD 6'b100001 - 90.0% of VDD 6'b100010 - 89.0% of VDD 6'b100011 - 88.0% of VDD 6'b100100 - 87.0% of VDD 6'b100101 - 86.0% of VDD 6'b100110 - 85.0% of VDD 6'b100111 - 84.0% of VDD 6'b101000 - 83.0% of VDD 6'b101001 - 82.0% of VDD 6'b101010 - 81.0% of VDD 6'b101011 - 80.0% of VDD 6'b101100 - 79.0% of VDD 6'b101101 - 78.0% of VDD 6'b101110 - 77.0% of VDD 6'b101111 - 76.0% of VDD 6'b110000 - 75.0% of VDD 6'b110001 - 74.0% of VDD 6'b110010 - 73.0% of VDD 6'b110011 - 72.0% of VDD 6'b110100 - 71.0% of VDD 6'b110101 - 70.0% of VDD 6'b110110 - 69.0% of VDD 6'b110111 - 68.0% of VDD 6'b111000 - 67.0% of VDD 6'b111001 - 66.0% of VDD 6'b111010 - 65.0% of VDD 6'b111011 - 64.0% of VDD 6'b111100 - 63.0% of VDD 6'b111101 - 62.0% of VDD 6'b111110 - 61.0% of VDD 6'b111111 - 60.0% of VDD
0x1A1D0 CFG0_VDD_MCU_GLDTC_STAT_PROXY ro — Shows the status of the voltage glitch detector circuit monitoring the VDD_MCU voltage domain
  [8] VDD_MCU_GLDTC_STAT_THRESH_HI_FLAG_PROXY — High voltage flag. This flag is cleared by clearing the VDD_MCU_GLDTC_CTRL_rstb bit. 0 - No high voltage detected 1 - Voltage above the high voltage threshold was detected.
  [0] VDD_MCU_GLDTC_STAT_THRESH_LOW_FLAG_PROXY — Low voltage flag. This flag is cleared by clearing the VDD_MCU_GLDTC_CTRL_rstb bit. 0 - No low voltage detected 1 - Voltage below the low voltage threshold was detected.
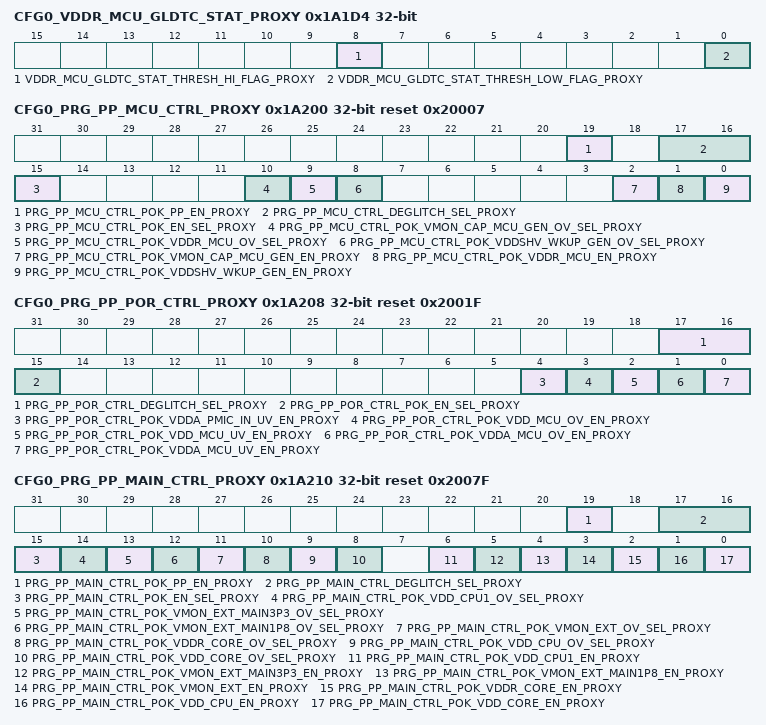
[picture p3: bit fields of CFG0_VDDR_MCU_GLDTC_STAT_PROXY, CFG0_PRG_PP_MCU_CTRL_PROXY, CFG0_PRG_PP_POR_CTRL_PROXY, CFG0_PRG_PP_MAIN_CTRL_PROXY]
0x1A1D4 CFG0_VDDR_MCU_GLDTC_STAT_PROXY ro — Shows the status of the voltage glitch detector circuit monitoring the VDDR_MCU voltage domain
  [8] VDDR_MCU_GLDTC_STAT_THRESH_HI_FLAG_PROXY — High voltage flag. This flag is cleared by clearing the VDDR_MCU_GLDTC_CTRL_rstb bit. 0 - No high voltage detected 1 - Voltage above the high voltage threshold was detected.
  [0] VDDR_MCU_GLDTC_STAT_THRESH_LOW_FLAG_PROXY — Low voltage flag. This flag is cleared by clearing the VDDR_MCU_GLDTC_CTRL_rstb bit. 0 - No low voltage detected 1 - Voltage below the low voltage threshold was detected.
0x1A200 CFG0_PRG_PP_MCU_CTRL_PROXY reset 0x20007 — Configures the MCU PRG_PP controller
  [19] PRG_PP_MCU_CTRL_POK_PP_EN_PROXY — POK ping-pong enable. When set, enables automatic switching between undervoltage and overvoltage detection on VDDSHV_WKUP_GENERAL, VDDR_MCU and VMON_CAP_MCU_GENERAL POKs. This bit has no effect if the POK's ov_sel bit = 1. 0 - No pingpong operation. UV/OV operation selected by each POK ov_sel bit 1 - Pingpong operation enabled .
  [17:16] PRG_PP_MCU_CTRL_DEGLITCH_SEL_PROXY — Deglitch period for PRG_PP_MCU POKs Field values (Others are reserved): 2'b00 - 5 us 2'b01 - 10 us 2'b10 - 15 us 2'b11 - 20 us
  [15] PRG_PP_MCU_CTRL_POK_EN_SEL_PROXY — Select POK enable source 0 - POK enables come from hardware tie-offs (tie-offs are 0 on this device so all POKs are disabled on power-up) 1 - POK enables come from PRG_PP_MCU_CTRL register
  [10] PRG_PP_MCU_CTRL_POK_VMON_CAP_MCU_GEN_OV_SEL_PROXY — Force VMON_CAP_MCU_GENERAL POK overvoltage detection. If this bit is 0 and pok_pp_en bit is also 0 then only undervoltage detection is enabled. 0 - Undervoltage detection or UV/OV ping-pong operation 1- Overvoltage detection only
  [9] PRG_PP_MCU_CTRL_POK_VDDR_MCU_OV_SEL_PROXY — Force VDDR_MCU POK overvoltage detection. If this bit is 0 and pok_pp_en bit is also 0 then only undervoltage detection is enabled. 0 - Undervoltage detection or UV/OV ping-pong operation 1- Overvoltage detection only
  [8] PRG_PP_MCU_CTRL_POK_VDDSHV_WKUP_GEN_OV_SEL_PROXY — Force VDDSHV_WKUP_GENERAL POK overvoltage detection. If this bit is 0 and pok_pp_en bit is also 0 then only undervoltage detection is enabled. 0 - Undervoltage detection or UV/OV ping-pong operation 1- Overvoltage detection only
  [2] PRG_PP_MCU_CTRL_POK_VMON_CAP_MCU_GEN_EN_PROXY — Enable VMON_CAP_MCU_GENERAL POK detection 0 - POK detection disabled 1 - POK detection enabled
  [1] PRG_PP_MCU_CTRL_POK_VDDR_MCU_EN_PROXY — Enable VDDR_MCU POK detection 0 - POK detection disabled 1 - POK detection enabled
  [0] PRG_PP_MCU_CTRL_POK_VDDSHV_WKUP_GEN_EN_PROXY — Enable VDDSHV_WKUP_GENERAL POK detection 0 - POK detection disabled 1 - POK detection enabled
0x1A208 CFG0_PRG_PP_POR_CTRL_PROXY reset 0x2001F — Configures the POR PRG_PP controller
  [17:16] PRG_PP_POR_CTRL_DEGLITCH_SEL_PROXY — Deglitch period for PRG_PP_POR POKs Field values (Others are reserved): 2'b00 - 5 us 2'b01 - 10 us 2'b10 - 15 us 2'b11 - 20 us
  [15] PRG_PP_POR_CTRL_POK_EN_SEL_PROXY — Select POK enable source 0 - POK enables come from hardware tie-offs (tie-offs are 0 on this device so all POKs are disabled on power-up) 1 - POK enables come from PRG_PP_POR_CTRL register
  [4] PRG_PP_POR_CTRL_POK_VDDA_PMIC_IN_UV_EN_PROXY — Enable VDDA_PMIC_IN undervoltage POK detection 0 - POK detection disabled 1 - POK detection enabled
  [3] PRG_PP_POR_CTRL_POK_VDD_MCU_OV_EN_PROXY — Enable VDD_MCU overvoltage POK detection 0 - POK detection disabled 1 - POK detection enabled
  [2] PRG_PP_POR_CTRL_POK_VDD_MCU_UV_EN_PROXY — Enable VDD_MCU undervoltage POK detection 0 - POK detection disabled 1 - POK detection enabled
  [1] PRG_PP_POR_CTRL_POK_VDDA_MCU_OV_EN_PROXY — Enable 1.8V VDDA_MCU overvoltage POK detection 0 - POK detection disabled 1 - POK detection enabled
  [0] PRG_PP_POR_CTRL_POK_VDDA_MCU_UV_EN_PROXY — Enable 1.8V VDDA_MCU undervoltage POK detection 0 - POK detection disabled 1 - POK detection enabled
0x1A210 CFG0_PRG_PP_MAIN_CTRL_PROXY reset 0x2007F — Configures the MAIN PRG_PP controller
  [19] PRG_PP_MAIN_CTRL_POK_PP_EN_PROXY — POK ping-pong enable. When set, enables automatic switching between undervoltage and overvoltage detection on VDD_CORE, VDD_CPU, VDDR_CORE, VMON_EXT, VMON_EXT_MAIN1P8 and VMON_EXT_MAIN3P3. This bit has no effect if the POK's ov_sel bit = 1. 0 - No pingpong operation. UV/OV operation selected by each POK ov_sel bit 1 - Pingpong operation enabled .
  [17:16] PRG_PP_MAIN_CTRL_DEGLITCH_SEL_PROXY — Deglitch period for PRG_PP_MAIN POKs Field values (Others are reserved): 2'b00 - 5 us 2'b01 - 10 us 2'b10 - 15 us 2'b11 - 20 us
  [15] PRG_PP_MAIN_CTRL_POK_EN_SEL_PROXY — Select POK enable source 0 - POK enables come from hardware tie-offs (tie-offs are 0 on this device so all POKs are disabled on power-up) 1 - POK enables come from PRG_PP_MAIN_CTRL register
  [14] PRG_PP_MAIN_CTRL_POK_VDD_CPU1_OV_SEL_PROXY — Force VDD_CPU1 POK overvoltage detection. If this bit is 0 and pok_pp_en bit is also 0 then only undervoltage detection is enabled. 0 - Undervoltage detection or UV/OV ping-pong operation 1- Overvoltage detection only
  [13] PRG_PP_MAIN_CTRL_POK_VMON_EXT_MAIN3P3_OV_SEL_PROXY — Force VMON_EXT_MAIN 3.3V POK overvoltage detection. If this bit is 0 and pok_pp_en bit is also 0 then only undervoltage detection is enabled. 0 - Undervoltage detection or UV/OV ping-pong operation 1- Overvoltage detection only
  [12] PRG_PP_MAIN_CTRL_POK_VMON_EXT_MAIN1P8_OV_SEL_PROXY — Force VMON_EXT_MAIN 1.8V POK overvoltage detection. If this bit is 0 and pok_pp_en bit is also 0 then only undervoltage detection is enabled. 0 - Undervoltage detection or UV/OV ping-pong operation 1- Overvoltage detection only
  [11] PRG_PP_MAIN_CTRL_POK_VMON_EXT_OV_SEL_PROXY — Force VMON_EXT POK overvoltage detection. If this bit is 0 and pok_pp_en bit is also 0 then only undervoltage detection is enabled. 0 - Undervoltage detection or UV/OV ping-pong operation 1- Overvoltage detection only
  [10] PRG_PP_MAIN_CTRL_POK_VDDR_CORE_OV_SEL_PROXY — Force VDDR_CORE POK overvoltage detection. If this bit is 0 and pok_pp_en bit is also 0 then only undervoltage detection is enabled. 0 - Undervoltage detection or UV/OV ping-pong operation 1- Overvoltage detection only
  [9] PRG_PP_MAIN_CTRL_POK_VDD_CPU_OV_SEL_PROXY — Force VDD_CPU POK overvoltage detection. If this bit is 0 and pok_pp_en bit is also 0 then only undervoltage detection is enabled. 0 - Undervoltage detection or UV/OV ping-pong operation 1- Overvoltage detection only
  [8] PRG_PP_MAIN_CTRL_POK_VDD_CORE_OV_SEL_PROXY — Force VDD_CORE POK overvoltage detection. If this bit is 0 and pok_pp_en bit is also 0 then only undervoltage detection is enabled. 0 - Undervoltage detection or UV/OV ping-pong operation 1- Overvoltage detection only
  [6] PRG_PP_MAIN_CTRL_POK_VDD_CPU1_EN_PROXY — Enable VDD_CPU1 POK detection 0 - POK detection disabled 1 - POK detection enabled
  [5] PRG_PP_MAIN_CTRL_POK_VMON_EXT_MAIN3P3_EN_PROXY — Enable VMON_EXT_MAIN 3.3V POK detection 0 - POK detection disabled 1 - POK detection enabled
  [4] PRG_PP_MAIN_CTRL_POK_VMON_EXT_MAIN1P8_EN_PROXY — Enable VMON_EXT_MAIN 1.8V POK detection 0 - POK detection disabled 1 - POK detection enabled
  [3] PRG_PP_MAIN_CTRL_POK_VMON_EXT_EN_PROXY — Enable VMON_EXT POK detection 0 - POK detection disabled 1 - POK detection enabled
  [2] PRG_PP_MAIN_CTRL_POK_VDDR_CORE_EN_PROXY — Enable VDDR_CORE POK detection 0 - POK detection disabled 1 - POK detection enabled
  [1] PRG_PP_MAIN_CTRL_POK_VDD_CPU_EN_PROXY — Enable VDD_CPU POK detection 0 - POK detection disabled 1 - POK detection enabled
  [0] PRG_PP_MAIN_CTRL_POK_VDD_CORE_EN_PROXY — Enable VDD_CORE POK detection 0 - POK detection disabled 1 - POK detection enabled
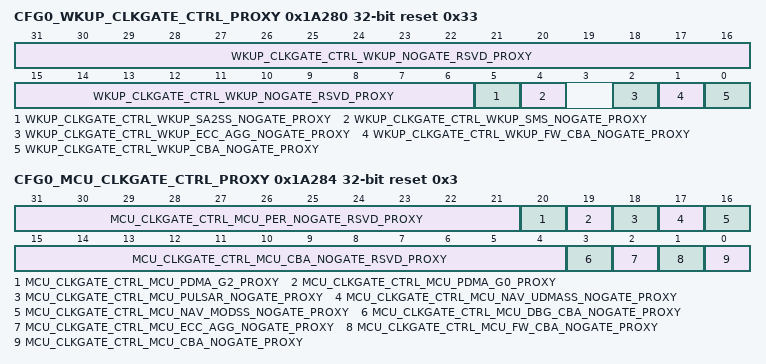
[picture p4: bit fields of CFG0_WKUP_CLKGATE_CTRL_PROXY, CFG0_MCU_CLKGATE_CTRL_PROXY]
0x1A280 CFG0_WKUP_CLKGATE_CTRL_PROXY reset 0x33 — Controls the power clock gating feature of WKUP domain modules and busses
  [31:6] WKUP_CLKGATE_CTRL_WKUP_NOGATE_RSVD_PROXY — WKUP reserved clock gate disable. These bits should remain unchanged (written only with their default value) to maintain compatibility with future devices. 0 - Clocks are gated on idle for power savings 1 - Clocks are not gated on idle, power saving disabled
  [5] WKUP_CLKGATE_CTRL_WKUP_SA2SS_NOGATE_PROXY — WKUP SA2SS clock gate disable 0 - Clocks are gated on idle for power savings 1 - Clocks are not gated on idle, power saving disabled
  [4] WKUP_CLKGATE_CTRL_WKUP_SMS_NOGATE_PROXY — WKUP SMS clock gate disable 0 - Clocks are gated on idle for power savings 1 - Clocks are not gated on idle, power saving disabled
  [2] WKUP_CLKGATE_CTRL_WKUP_ECC_AGG_NOGATE_PROXY — WKUP ECC Aggregator clock gate disable 0 - Clocks are gated on idle for power savings 1 - Clocks are not gated on idle, power saving disabled
  [1] WKUP_CLKGATE_CTRL_WKUP_FW_CBA_NOGATE_PROXY — WKUP domain Firewall bus (wkup_fw_cbass) clock gate disable 0 - Clocks are gated on idle for power savings 1 - Clocks are not gated on idle, power saving disabled
  [0] WKUP_CLKGATE_CTRL_WKUP_CBA_NOGATE_PROXY — WKUP domain Data bus (wkup_cbass) clock gate disable 0 - Clocks are gated on idle for power savings 1 - Clocks are not gated on idle, power saving disabled
0x1A284 CFG0_MCU_CLKGATE_CTRL_PROXY reset 0x3 — Controls the power clock gating feature of MCU domain modules and busses
  [31:21] MCU_CLKGATE_CTRL_MCU_PER_NOGATE_RSVD_PROXY — MCU reserved clock gate disable. These bits should remain unchanged (written only with their default value) to maintain compatibility with future devices. 0 - Clocks are gated on idle for power savings 1 - Clocks are not gated on idle, power saving disabled
  [20] MCU_CLKGATE_CTRL_MCU_PDMA_G2_PROXY — MCU domain MCAN1/USART0 PDMA clock gate disable. 0 - Clocks are gated on idle for power savings 1 - Clocks are not gated on idle, power saving disabled
  [19] MCU_CLKGATE_CTRL_MCU_PDMA_G0_PROXY — MCU domain MCAN0/SPI0 PDMA clock gate disable. 0 - Clocks are gated on idle for power savings 1 - Clocks are not gated on idle, power saving disabled
  [18] MCU_CLKGATE_CTRL_MCU_PULSAR_NOGATE_PROXY — MCU domain Pulsar clock gate disable. 0 - Clocks are gated on idle for power savings 1 - Clocks are not gated on idle, power saving disabled
  [17] MCU_CLKGATE_CTRL_MCU_NAV_UDMASS_NOGATE_PROXY — MCU NavSS UDMA interface clock gate disable. 0 - Clocks are gated on idle for power savings 1 - Clocks are not gated on idle, power saving disabled
  [16] MCU_CLKGATE_CTRL_MCU_NAV_MODSS_NOGATE_PROXY — MCU NavSS MODSS interface clock gate disable. 0 - Clocks are gated on idle for power savings 1 - Clocks are not gated on idle, power saving disabled
  [15:4] MCU_CLKGATE_CTRL_MCU_CBA_NOGATE_RSVD_PROXY — MCU reserved clock gate disable. These bits should remain unchanged (written only with their default value) to maintain compatibility with future devices. 0 - Clocks are gated on idle for power savings 1 - Clocks are not gated on idle, power saving disabled
  [3] MCU_CLKGATE_CTRL_MCU_DBG_CBA_NOGATE_PROXY — MCU domain Debug bus (mcu_dbg_cbass) clock gate disable. 0 - Clocks are gated on idle for power savings 1 - Clocks are not gated on idle, power saving disabled
  [2] MCU_CLKGATE_CTRL_MCU_ECC_AGG_NOGATE_PROXY — MCU ECC Aggregator clock gate disable 0 - Clocks are gated on idle for power savings 1 - Clocks are not gated on idle, power saving disabled
  [1] MCU_CLKGATE_CTRL_MCU_FW_CBA_NOGATE_PROXY — MCU domain Firewall bus (mcu_fw_cbass) clock gate disable. 0 - Clocks are gated on idle for power savings 1 - Clocks are not gated on idle, power saving disabled
  [0] MCU_CLKGATE_CTRL_MCU_CBA_NOGATE_PROXY — MCU domain Data bus (mcu_cbass) clock gate disable. 0 - Clocks are gated on idle for power savings 1 - Clocks are not gated on idle, power saving disabled
